VERSION "HIPBNYYYYYYYYYYYYYYYYYYYYYYYYYYYYYYYYYYYYY/4/%%%/4/'%**4YYY///"

NS_ :

BS_:

BU_: shock_pots

BO_ 160 shock_pots: 8 shock_pots
 SG_ shockpot1 : 0|8@1+ (1,0) [0|0] "mm" Vector__XXX
 SG_ shockpot2 : 8|8@1+ (1,0) [0|0] "mm" Vector__XXX

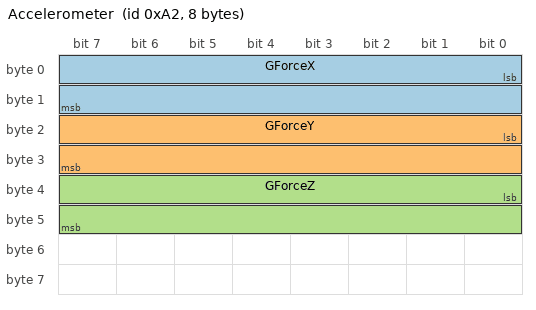
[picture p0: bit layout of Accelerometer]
BO_ 162 Accelerometer: 8 shock_pots
 SG_ GForceX : 0|16@1+ (1000,10000) [0|0] "Gs" Vector__XXX
 SG_ GForceY : 16|16@1+ (1000,10000) [0|0] "Gs" Vector__XXX
 SG_ GForceZ : 32|16@1+ (1000,10000) [0|0] "Gs" Vector__XXX
